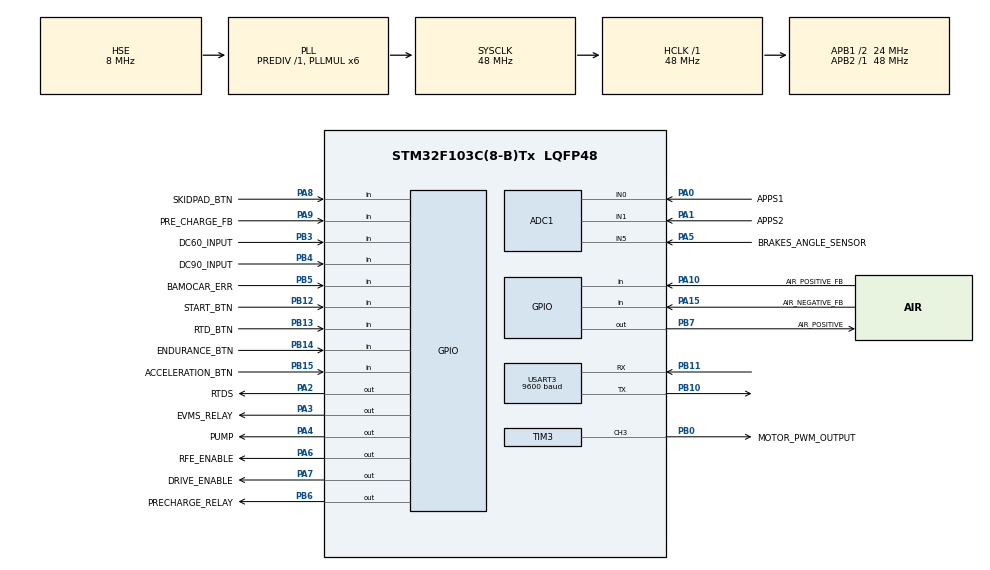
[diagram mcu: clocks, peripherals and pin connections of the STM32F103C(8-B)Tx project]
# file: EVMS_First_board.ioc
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ADC1.Channel-0\#ChannelRegularConversion=ADC_CHANNEL_0
ADC1.Channel-1\#ChannelRegularConversion=ADC_CHANNEL_1
ADC1.Channel-2\#ChannelRegularConversion=ADC_CHANNEL_5
ADC1.ContinuousConvMode=ENABLE
ADC1.DataAlign=ADC_DATAALIGN_RIGHT
ADC1.NbrOfConversion=3
ADC1.NbrOfConversionFlag=1
ADC1.Rank-0\#ChannelRegularConversion=1
ADC1.Rank-1\#ChannelRegularConversion=2
ADC1.Rank-2\#ChannelRegularConversion=3
ADC1.SamplingTime-0\#ChannelRegularConversion=ADC_SAMPLETIME_71CYCLES_5
ADC1.SamplingTime-1\#ChannelRegularConversion=ADC_SAMPLETIME_71CYCLES_5
ADC1.SamplingTime-2\#ChannelRegularConversion=ADC_SAMPLETIME_71CYCLES_5
ADC1.master=1
Dma.ADC1.0.Direction=DMA_PERIPH_TO_MEMORY
Dma.ADC1.0.Instance=DMA1_Channel1
Dma.ADC1.0.MemDataAlignment=DMA_MDATAALIGN_HALFWORD
Dma.ADC1.0.MemInc=DMA_MINC_ENABLE
Dma.ADC1.0.Mode=DMA_CIRCULAR
Dma.ADC1.0.PeriphDataAlignment=DMA_PDATAALIGN_HALFWORD
Dma.ADC1.0.PeriphInc=DMA_PINC_DISABLE
Dma.ADC1.0.Priority=DMA_PRIORITY_LOW
Dma.Request0=ADC1
Mcu.Family=STM32F1
Mcu.Name=STM32F103C(8-B)Tx
Mcu.Package=LQFP48
NVIC.DMA1_Channel1_IRQn=true\:1\:0\:true\:false\:true\:false\:true\:true
NVIC.PriorityGroup=NVIC_PRIORITYGROUP_4
NVIC.TIM1_UP_IRQn=true\:0\:0\:true\:false\:true\:false\:true\:true
NVIC.TimeBase=TIM1_UP_IRQn
NVIC.TimeBaseIP=TIM1
PA0-WKUP.GPIO_Label=APPS1
PA0-WKUP.Signal=ADCx_IN0
PA1.GPIO_Label=APPS2
PA1.Signal=ADCx_IN1
PA10.GPIO_Label=AIR_POSITIVE_FB
PA10.Signal=GPIO_Input
PA15.GPIO_Label=AIR_NEGATIVE_FB
PA15.Signal=GPIO_Input
PA2.GPIO_Label=RTDS
PA2.Signal=GPIO_Output
PA3.GPIO_Label=EVMS_RELAY
PA3.Signal=GPIO_Output
PA4.GPIO_Label=PUMP
PA4.Signal=GPIO_Output
PA5.GPIO_Label=BRAKES_ANGLE_SENSOR
PA5.Signal=ADCx_IN5
PA6.GPIO_Label=RFE_ENABLE
PA6.Signal=GPIO_Output
PA7.GPIO_Label=DRIVE_ENABLE
PA7.Signal=GPIO_Output
PA8.GPIO_Label=SKIDPAD_BTN
PA8.Signal=GPIO_Input
PA9.GPIO_Label=PRE_CHARGE_FB
PA9.Signal=GPIO_Input
PB0.GPIO_Label=MOTOR_PWM_OUTPUT
PB0.Signal=S_TIM3_CH3
PB10.Mode=Asynchronous
PB10.Signal=USART3_TX
PB11.Mode=Asynchronous
PB11.Signal=USART3_RX
PB12.GPIO_Label=START_BTN
PB12.Signal=GPIO_Input
PB13.GPIO_Label=RTD_BTN
PB13.Signal=GPIO_Input
PB14.GPIO_Label=ENDURANCE_BTN
PB14.Signal=GPIO_Input
PB15.GPIO_Label=ACCELERATION_BTN
PB15.Signal=GPIO_Input
PB3.GPIO_Label=DC60_INPUT
PB3.Signal=GPIO_Input
PB4.GPIO_Label=DC90_INPUT
PB4.Signal=GPIO_Input
PB5.GPIO_Label=BAMOCAR_ERR
PB5.Signal=GPIO_Input
PB6.GPIO_Label=PRECHARGE_RELAY
PB6.Signal=GPIO_Output
PB7.GPIO_Label=AIR_POSITIVE
PB7.Signal=GPIO_Output
PD0-OSC_IN.Mode=HSE-External-Oscillator
PD0-OSC_IN.Signal=RCC_OSC_IN
PD1-OSC_OUT.Mode=HSE-External-Oscillator
PD1-OSC_OUT.Signal=RCC_OSC_OUT
ProjectManager.HeapSize=0x200
ProjectManager.StackSize=0x400
ProjectManager.TargetToolchain=STM32CubeIDE
RCC.ADCPresc=RCC_ADCPCLK2_DIV4
RCC.AHBFreq_Value=48000000
RCC.APB1CLKDivider=RCC_HCLK_DIV2
RCC.APB1Freq_Value=24000000
RCC.APB1TimFreq_Value=48000000
RCC.APB2Freq_Value=48000000
RCC.APB2TimFreq_Value=48000000
RCC.HCLKFreq_Value=48000000
RCC.PLLMUL=RCC_PLL_MUL6
RCC.PLLSourceVirtual=RCC_PLLSOURCE_HSE
RCC.SYSCLKFreq_VALUE=48000000
RCC.SYSCLKSource=RCC_SYSCLKSOURCE_PLLCLK
RCC.USBFreq_Value=48000000
SH.ADCx_IN0.0=ADC1_IN0,IN0
SH.ADCx_IN1.0=ADC1_IN1,IN1
SH.ADCx_IN5.0=ADC1_IN5,IN5
SH.S_TIM3_CH3.0=TIM3_CH3,PWM Generation3 CH3
TIM3.AutoReloadPreload=TIM_AUTORELOAD_PRELOAD_DISABLE
TIM3.Channel-PWM\ Generation3\ CH3=TIM_CHANNEL_3
TIM3.CounterMode=TIM_COUNTERMODE_UP
TIM3.Period=199
TIM3.Prescaler=3
TIM3.Pulse-PWM\ Generation3\ CH3=0
USART3.BaudRate=9600
USART3.VirtualMode=VM_ASYNC
VP_SYS_VS_tim1.Mode=TIM1
board=custom

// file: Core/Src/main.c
/* USER CODE BEGIN Header */
/**
 ******************************************************************************
 * @file           : main.c
 * @brief          : Main program body
 ******************************************************************************
 * @attention
 *
 * Copyright (c) 2023 STMicroelectronics.
 * All rights reserved.
 *
 * This software is licensed under terms that can be found in the LICENSE file
 * in the root directory of this software component.
 * If no LICENSE file comes with this software, it is provided AS-IS.
 *
 ******************************************************************************
 */
/* USER CODE END Header */
#include "main.h"

/* USER CODE BEGIN Includes */
#include "EVMS.h"
#include "DEBUG_UTILS.h"
/* USER CODE END Includes */

ADC_HandleTypeDef hadc1;
DMA_HandleTypeDef hdma_adc1;

TIM_HandleTypeDef htim3;

UART_HandleTypeDef huart3;

void SystemClock_Config(void);
static void MX_GPIO_Init(void);
static void MX_DMA_Init(void);
static void MX_ADC1_Init(void);
static void MX_TIM3_Init(void);
static void MX_USART3_UART_Init(void);

int main(void)
{

  /* MCU Configuration--------------------------------------------------------*/

  /* Reset of all peripherals, Initializes the Flash interface and the Systick. */
  HAL_Init();

  /* Configure the system clock */
  SystemClock_Config();

  /* Initialize all configured peripherals */
  MX_GPIO_Init();
  MX_DMA_Init();
  MX_ADC1_Init();
  MX_TIM3_Init();
  MX_USART3_UART_Init();
  /* USER CODE BEGIN 2 */
	HAL_ADC_Start_DMA(&hadc1, ADC_values, 3);
	HAL_TIM_Base_Start(&htim3);
	HAL_TIM_PWM_Start(&htim3, TIM_CHANNEL_3);

  /* USER CODE END 2 */

  /* Infinite loop */
  /* USER CODE BEGIN WHILE */
//		EVMS_Init();
//	HAL_Delay(5000);
//	DEBUG_INFO("Entering super loop...");

	while (1) {

		/* start looping on the different conditions */
		loop();
    /* USER CODE END WHILE */

	}
}

void SystemClock_Config(void)
{
  RCC_OscInitTypeDef RCC_OscInitStruct = {0};
  RCC_ClkInitTypeDef RCC_ClkInitStruct = {0};
  RCC_PeriphCLKInitTypeDef PeriphClkInit = {0};

  /** Initializes the RCC Oscillators according to the specified parameters
  * in the RCC_OscInitTypeDef structure.
  */
  RCC_OscInitStruct.OscillatorType = RCC_OSCILLATORTYPE_HSE;
  RCC_OscInitStruct.HSEState = RCC_HSE_ON;
  RCC_OscInitStruct.HSEPredivValue = RCC_HSE_PREDIV_DIV1;
  RCC_OscInitStruct.HSIState = RCC_HSI_ON;
  RCC_OscInitStruct.PLL.PLLState = RCC_PLL_ON;
  RCC_OscInitStruct.PLL.PLLSource = RCC_PLLSOURCE_HSE;
  RCC_OscInitStruct.PLL.PLLMUL = RCC_PLL_MUL6;
  if (HAL_RCC_OscConfig(&RCC_OscInitStruct) != HAL_OK)
  {
    Error_Handler();
  }

  /** Initializes the CPU, AHB and APB buses clocks
  */
  RCC_ClkInitStruct.ClockType = RCC_CLOCKTYPE_HCLK|RCC_CLOCKTYPE_SYSCLK
                              |RCC_CLOCKTYPE_PCLK1|RCC_CLOCKTYPE_PCLK2;
  RCC_ClkInitStruct.SYSCLKSource = RCC_SYSCLKSOURCE_PLLCLK;
  RCC_ClkInitStruct.AHBCLKDivider = RCC_SYSCLK_DIV1;
  RCC_ClkInitStruct.APB1CLKDivider = RCC_HCLK_DIV2;
  RCC_ClkInitStruct.APB2CLKDivider = RCC_HCLK_DIV1;

  if (HAL_RCC_ClockConfig(&RCC_ClkInitStruct, FLASH_LATENCY_1) != HAL_OK)
  {
    Error_Handler();
  }
  PeriphClkInit.PeriphClockSelection = RCC_PERIPHCLK_ADC;
  PeriphClkInit.AdcClockSelection = RCC_ADCPCLK2_DIV4;
  if (HAL_RCCEx_PeriphCLKConfig(&PeriphClkInit) != HAL_OK)
  {
    Error_Handler();
  }
}

static void MX_ADC1_Init(void)
{

  ADC_ChannelConfTypeDef sConfig = {0};

  /** Common config
  */
  hadc1.Instance = ADC1;
  hadc1.Init.ScanConvMode = ADC_SCAN_ENABLE;
  hadc1.Init.ContinuousConvMode = ENABLE;
  hadc1.Init.DiscontinuousConvMode = DISABLE;
  hadc1.Init.ExternalTrigConv = ADC_SOFTWARE_START;
  hadc1.Init.DataAlign = ADC_DATAALIGN_RIGHT;
  hadc1.Init.NbrOfConversion = 3;
  if (HAL_ADC_Init(&hadc1) != HAL_OK)
  {
    Error_Handler();
  }

  /** Configure Regular Channel
  */
  sConfig.Channel = ADC_CHANNEL_0;
  sConfig.Rank = ADC_REGULAR_RANK_1;
  sConfig.SamplingTime = ADC_SAMPLETIME_71CYCLES_5;
  if (HAL_ADC_ConfigChannel(&hadc1, &sConfig) != HAL_OK)
  {
    Error_Handler();
  }

  /** Configure Regular Channel
  */
  sConfig.Channel = ADC_CHANNEL_1;
  sConfig.Rank = ADC_REGULAR_RANK_2;
  if (HAL_ADC_ConfigChannel(&hadc1, &sConfig) != HAL_OK)
  {
    Error_Handler();
  }

  /** Configure Regular Channel
  */
  sConfig.Channel = ADC_CHANNEL_5;
  sConfig.Rank = ADC_REGULAR_RANK_3;
  if (HAL_ADC_ConfigChannel(&hadc1, &sConfig) != HAL_OK)
  {
    Error_Handler();
  }

}

static void MX_TIM3_Init(void)
{

  TIM_MasterConfigTypeDef sMasterConfig = {0};
  TIM_OC_InitTypeDef sConfigOC = {0};

  htim3.Instance = TIM3;
  htim3.Init.Prescaler = 3;
  htim3.Init.CounterMode = TIM_COUNTERMODE_UP;
  htim3.Init.Period = 199;
  htim3.Init.ClockDivision = TIM_CLOCKDIVISION_DIV1;
  htim3.Init.AutoReloadPreload = TIM_AUTORELOAD_PRELOAD_DISABLE;
  if (HAL_TIM_PWM_Init(&htim3) != HAL_OK)
  {
    Error_Handler();
  }
  sMasterConfig.MasterOutputTrigger = TIM_TRGO_RESET;
  sMasterConfig.MasterSlaveMode = TIM_MASTERSLAVEMODE_DISABLE;
  if (HAL_TIMEx_MasterConfigSynchronization(&htim3, &sMasterConfig) != HAL_OK)
  {
    Error_Handler();
  }
  sConfigOC.OCMode = TIM_OCMODE_PWM1;
  sConfigOC.Pulse = 0;
  sConfigOC.OCPolarity = TIM_OCPOLARITY_HIGH;
  sConfigOC.OCFastMode = TIM_OCFAST_DISABLE;
  if (HAL_TIM_PWM_ConfigChannel(&htim3, &sConfigOC, TIM_CHANNEL_3) != HAL_OK)
  {
    Error_Handler();
  }
  HAL_TIM_MspPostInit(&htim3);

}

static void MX_USART3_UART_Init(void)
{

  huart3.Instance = USART3;
  huart3.Init.BaudRate = 9600;
  huart3.Init.WordLength = UART_WORDLENGTH_8B;
  huart3.Init.StopBits = UART_STOPBITS_1;
  huart3.Init.Parity = UART_PARITY_NONE;
  huart3.Init.Mode = UART_MODE_TX_RX;
  huart3.Init.HwFlowCtl = UART_HWCONTROL_NONE;
  huart3.Init.OverSampling = UART_OVERSAMPLING_16;
  if (HAL_UART_Init(&huart3) != HAL_OK)
  {
    Error_Handler();
  }

}

static void MX_DMA_Init(void)
{

  /* DMA controller clock enable */
  __HAL_RCC_DMA1_CLK_ENABLE();

  /* DMA interrupt init */
  /* DMA1_Channel1_IRQn interrupt configuration */
  HAL_NVIC_SetPriority(DMA1_Channel1_IRQn, 1, 0);
  HAL_NVIC_EnableIRQ(DMA1_Channel1_IRQn);

}

static void MX_GPIO_Init(void)
{
  GPIO_InitTypeDef GPIO_InitStruct = {0};

  /* GPIO Ports Clock Enable */
  __HAL_RCC_GPIOD_CLK_ENABLE();
  __HAL_RCC_GPIOA_CLK_ENABLE();
  __HAL_RCC_GPIOB_CLK_ENABLE();

  /*Configure GPIO pin Output Level */
  HAL_GPIO_WritePin(GPIOA, RTDS_Pin|EVMS_RELAY_Pin|PUMP_Pin|RFE_ENABLE_Pin
                          |DRIVE_ENABLE_Pin, GPIO_PIN_RESET);

  /*Configure GPIO pin Output Level */
  HAL_GPIO_WritePin(GPIOB, PRECHARGE_RELAY_Pin|AIR_POSITIVE_Pin, GPIO_PIN_RESET);

  /*Configure GPIO pins : RTDS_Pin EVMS_RELAY_Pin PUMP_Pin RFE_ENABLE_Pin
                           DRIVE_ENABLE_Pin */
  GPIO_InitStruct.Pin = RTDS_Pin|EVMS_RELAY_Pin|PUMP_Pin|RFE_ENABLE_Pin
                          |DRIVE_ENABLE_Pin;
  GPIO_InitStruct.Mode = GPIO_MODE_OUTPUT_PP;
  GPIO_InitStruct.Pull = GPIO_NOPULL;
  GPIO_InitStruct.Speed = GPIO_SPEED_FREQ_LOW;
  HAL_GPIO_Init(GPIOA, &GPIO_InitStruct);

  /*Configure GPIO pins : START_BTN_Pin RTD_BTN_Pin ENDURANCE_BTN_Pin ACCELERATION_BTN_Pin
                           DC60_INPUT_Pin DC90_INPUT_Pin BAMOCAR_ERR_Pin */
  GPIO_InitStruct.Pin = START_BTN_Pin|RTD_BTN_Pin|ENDURANCE_BTN_Pin|ACCELERATION_BTN_Pin
                          |DC60_INPUT_Pin|DC90_INPUT_Pin|BAMOCAR_ERR_Pin;
  GPIO_InitStruct.Mode = GPIO_MODE_INPUT;
  GPIO_InitStruct.Pull = GPIO_NOPULL;
  HAL_GPIO_Init(GPIOB, &GPIO_InitStruct);

  /*Configure GPIO pins : SKIDPAD_BTN_Pin PRE_CHARGE_FB_Pin AIR_POSITIVE_FB_Pin AIR_NEGATIVE_FB_Pin */
  GPIO_InitStruct.Pin = SKIDPAD_BTN_Pin|PRE_CHARGE_FB_Pin|AIR_POSITIVE_FB_Pin|AIR_NEGATIVE_FB_Pin;
  GPIO_InitStruct.Mode = GPIO_MODE_INPUT;
  GPIO_InitStruct.Pull = GPIO_NOPULL;
  HAL_GPIO_Init(GPIOA, &GPIO_InitStruct);

  /*Configure GPIO pins : PRECHARGE_RELAY_Pin AIR_POSITIVE_Pin */
  GPIO_InitStruct.Pin = PRECHARGE_RELAY_Pin|AIR_POSITIVE_Pin;
  GPIO_InitStruct.Mode = GPIO_MODE_OUTPUT_PP;
  GPIO_InitStruct.Pull = GPIO_NOPULL;
  GPIO_InitStruct.Speed = GPIO_SPEED_FREQ_LOW;
  HAL_GPIO_Init(GPIOB, &GPIO_InitStruct);

}

void HAL_TIM_PeriodElapsedCallback(TIM_HandleTypeDef *htim)
{
  if (htim->Instance == TIM1) {
    HAL_IncTick();
  }
}

void Error_Handler(void)
{
	__disable_irq();
	while (1) {
	}
}
